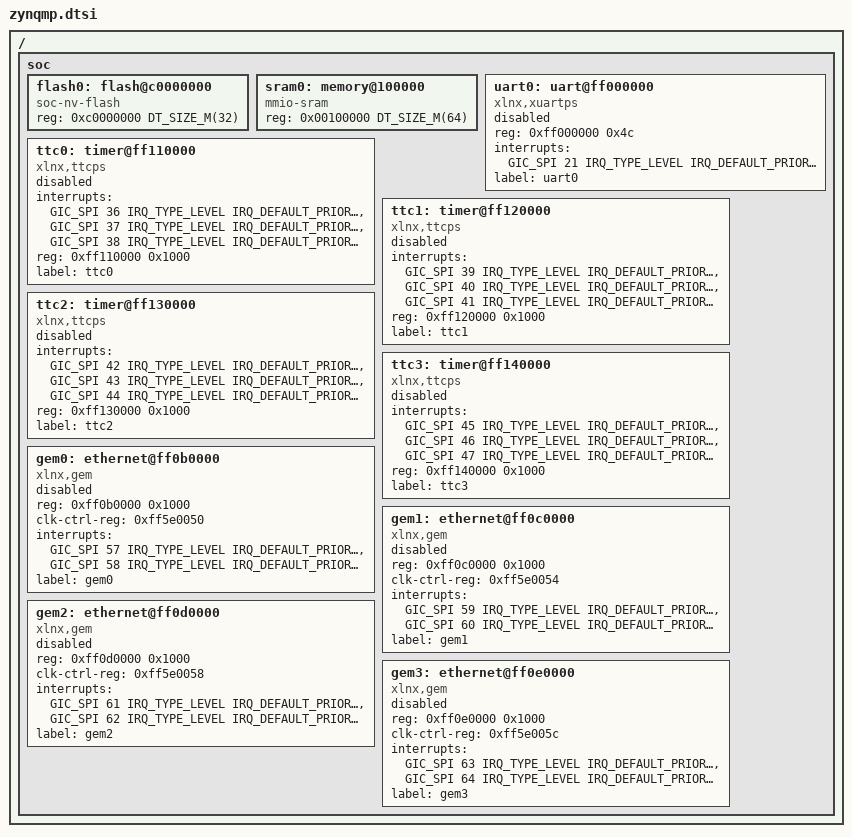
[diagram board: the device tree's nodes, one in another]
/*
 * Copyright (c) 2019 Lexmark International, Inc.
 * Copyright (c) 2020, Weidmueller Interface GmbH & Co. KG
 *
 * SPDX-License-Identifier: Apache-2.0
 */

#include <mem.h>
#include <arm/armv7-r.dtsi>
#include <dt-bindings/interrupt-controller/arm-gic.h>

/ {
	soc {
		flash0: flash@c0000000 {
			compatible = "soc-nv-flash";
			reg = <0xc0000000 DT_SIZE_M(32)>;
		};

		sram0: memory@100000 {
			compatible = "mmio-sram";
			reg = <0x00100000 DT_SIZE_M(64)>;
		};

		uart0: uart@ff000000 {
			compatible = "xlnx,xuartps";
			reg = <0xff000000 0x4c>;
			status = "disabled";
			interrupts = <GIC_SPI 21 IRQ_TYPE_LEVEL
					IRQ_DEFAULT_PRIORITY>;
			interrupt-names = "irq_0";
			label = "uart0";
		};

		ttc0: timer@ff110000 {
			compatible = "xlnx,ttcps";
			status = "disabled";
			interrupts = <GIC_SPI 36 IRQ_TYPE_LEVEL
					IRQ_DEFAULT_PRIORITY>,
				     <GIC_SPI 37 IRQ_TYPE_LEVEL
					IRQ_DEFAULT_PRIORITY>,
				     <GIC_SPI 38 IRQ_TYPE_LEVEL
					IRQ_DEFAULT_PRIORITY>;
			interrupt-names = "irq_0", "irq_1", "irq_2";
			reg = <0xff110000 0x1000>;
			label = "ttc0";
		};

		ttc1: timer@ff120000 {
			compatible = "xlnx,ttcps";
			status = "disabled";
			interrupts = <GIC_SPI 39 IRQ_TYPE_LEVEL
					IRQ_DEFAULT_PRIORITY>,
				     <GIC_SPI 40 IRQ_TYPE_LEVEL
					IRQ_DEFAULT_PRIORITY>,
				     <GIC_SPI 41 IRQ_TYPE_LEVEL
					IRQ_DEFAULT_PRIORITY>;
			interrupt-names = "irq_0", "irq_1", "irq_2";
			reg = <0xff120000 0x1000>;
			label = "ttc1";
		};

		ttc2: timer@ff130000 {
			compatible = "xlnx,ttcps";
			status = "disabled";
			interrupts = <GIC_SPI 42 IRQ_TYPE_LEVEL
					IRQ_DEFAULT_PRIORITY>,
				     <GIC_SPI 43 IRQ_TYPE_LEVEL
					IRQ_DEFAULT_PRIORITY>,
				     <GIC_SPI 44 IRQ_TYPE_LEVEL
					IRQ_DEFAULT_PRIORITY>;
			interrupt-names = "irq_0", "irq_1", "irq_2";
			reg = <0xff130000 0x1000>;
			label = "ttc2";
		};

		ttc3: timer@ff140000 {
			compatible = "xlnx,ttcps";
			status = "disabled";
			interrupts = <GIC_SPI 45 IRQ_TYPE_LEVEL
					IRQ_DEFAULT_PRIORITY>,
				     <GIC_SPI 46 IRQ_TYPE_LEVEL
					IRQ_DEFAULT_PRIORITY>,
				     <GIC_SPI 47 IRQ_TYPE_LEVEL
					IRQ_DEFAULT_PRIORITY>;
			interrupt-names = "irq_0", "irq_1", "irq_2";
			reg = <0xff140000 0x1000>;
			label = "ttc3";
		};

		gem0: ethernet@ff0b0000 {
			compatible = "xlnx,gem";
			reg = <0xff0b0000 0x1000>;
			clk-ctrl-reg = <0xff5e0050>;
			status = "disabled";
			interrupts = <GIC_SPI 57 IRQ_TYPE_LEVEL 
					IRQ_DEFAULT_PRIORITY>,
				     <GIC_SPI 58 IRQ_TYPE_LEVEL 
					IRQ_DEFAULT_PRIORITY>;
			interrupt-names = "irq_0", "irq_1";
			label = "gem0";
		};

		gem1: ethernet@ff0c0000 {
			compatible = "xlnx,gem";
			reg = <0xff0c0000 0x1000>;
			clk-ctrl-reg = <0xff5e0054>;
			status = "disabled";
			interrupts = <GIC_SPI 59 IRQ_TYPE_LEVEL 
					IRQ_DEFAULT_PRIORITY>,
				     <GIC_SPI 60 IRQ_TYPE_LEVEL 
					IRQ_DEFAULT_PRIORITY>;
			interrupt-names = "irq_0", "irq_1";
			label = "gem1";
		};

		gem2: ethernet@ff0d0000 {
			compatible = "xlnx,gem";
			reg = <0xff0d0000 0x1000>;
			clk-ctrl-reg = <0xff5e0058>;
			status = "disabled";
			interrupts = <GIC_SPI 61 IRQ_TYPE_LEVEL 
					IRQ_DEFAULT_PRIORITY>,
				     <GIC_SPI 62 IRQ_TYPE_LEVEL 
					IRQ_DEFAULT_PRIORITY>;
			interrupt-names = "irq_0", "irq_1";
			label = "gem2";
		};

		gem3: ethernet@ff0e0000 {
			compatible = "xlnx,gem";
			reg = <0xff0e0000 0x1000>;
			clk-ctrl-reg = <0xff5e005c>;
			status = "disabled";
			interrupts = <GIC_SPI 63 IRQ_TYPE_LEVEL 
					IRQ_DEFAULT_PRIORITY>,
				     <GIC_SPI 64 IRQ_TYPE_LEVEL 
					IRQ_DEFAULT_PRIORITY>;
			interrupt-names = "irq_0", "irq_1";
			label = "gem3";
		};
	};
};
